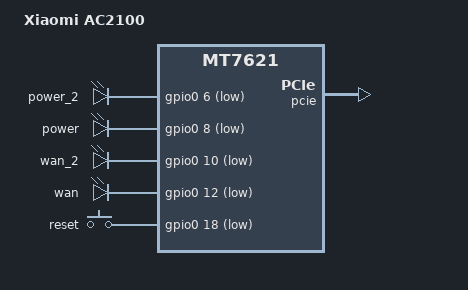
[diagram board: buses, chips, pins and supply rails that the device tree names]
/dts-v1/;

#include "mt7621.dtsi"
#include <dt-bindings/input/input.h>
#include "mt7621-raeth-gmac2.dtsi"
#include "mt7621-pinctrl-default-gpio.dtsi"
#include "mt7621-nand-128m-layout.dtsi"

/ {
	compatible = "mediatek,mt7621-soc";
	model = "Xiaomi AC2100";

	chosen {
		bootargs = "console=ttyS0,115200";
	};

	leds {
		compatible = "gpio-leds";

		sys_yellow {
			label = "power_2";
			gpios = <&gpio0 6 GPIO_ACTIVE_LOW>;
		};

		sys_blue {
			label = "power";
			gpios = <&gpio0 8 GPIO_ACTIVE_LOW>;
		};

		net_yellow {
			label = "wan_2";
			gpios = <&gpio0 10 GPIO_ACTIVE_LOW>;
		};

		net_blue {
			label = "wan";
			gpios = <&gpio0 12 GPIO_ACTIVE_LOW>;
		};
	};

	gpio-keys-polled {
		compatible = "gpio-keys-polled";
		#address-cells = <1>;
		#size-cells = <0>;
		poll-interval = <20>;

		reset {
			label = "reset";
			gpios = <&gpio0 18 GPIO_ACTIVE_LOW>;
			linux,code = <KEY_RESTART>;
		};

	};
};

&pcie {
	status = "okay";
};

/* R2100 NAND uses sdhci pins (nand2) only. Remove spi-nand group since
   NAND is not connected to SPI pins on this board. */
&pinctrl {
	nand_pins: nand {
		/delete-node/ spi-nand;
		sdhci-nand {
			mtk,group = "sdhci";
			mtk,function = "nand2";
		};
	};
};
